# MCU_CPT2_AGGR0_STP2ATB_CFG register map
Vendor: Texas Instruments
Peripheral module from a debugger description file (folder am62P).
Registers are 32-bit, access per field, reset 0x4 unless marked. A register's access mark holds for its fields unless they carry their own. Offsets are as the file gives them; lines under a group give offsets from that group; [hi:lo] are bit positions; {n}, {i} and the like mark numbered series; 'fields as' and 'values as' point back to an identical list; <NAME> marks a mode.

## MCU_CPT2_AGGR0_STP2ATB_CFG
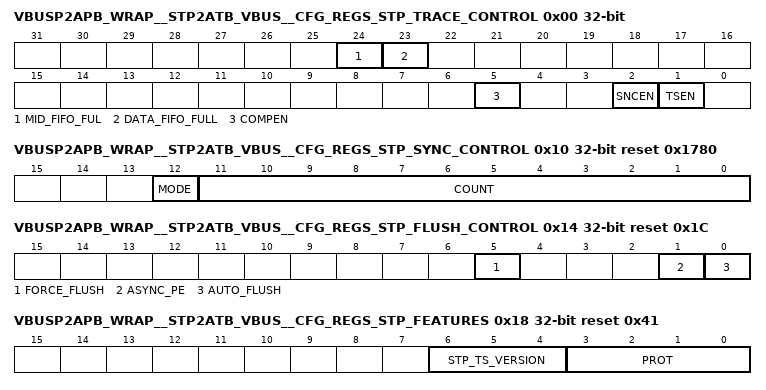
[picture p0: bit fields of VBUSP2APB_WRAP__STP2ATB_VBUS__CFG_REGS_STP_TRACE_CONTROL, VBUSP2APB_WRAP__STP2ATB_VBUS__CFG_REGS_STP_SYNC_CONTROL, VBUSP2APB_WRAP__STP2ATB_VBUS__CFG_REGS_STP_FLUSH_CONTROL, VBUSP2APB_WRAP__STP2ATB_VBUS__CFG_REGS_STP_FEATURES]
0x00 VBUSP2APB_WRAP__STP2ATB_VBUS__CFG_REGS_STP_TRACE_CONTROL — This register contains the control and status settings for STP Trace control register. MID_Fifofull indicates status of internal Initiator/Channel Fifo as full. Data_Fifofull indicates the status of internal Data Fifo as full. It is possible that if MID_Fifofull is full and when new initiator_id is seen on STPMI i/f, the data will not be accepted as MID is full. It will wait for MID to be read out corresponding to Data.
  [24] MID_FIFO_FUL ro, [23] DATA_FIFO_FULL ro, [5] COMPEN rw, [2] SNCEN ro, [1] TSEN rw
0x04 VBUSP2APB_WRAP__STP2ATB_VBUS__CFG_REGS_STP_TRACE_ID reset 0x0 — This register contains the trace id register settings. This value is sampled from input and is exported on ATB interface as ATID field. This is usually programmed only when top-level configuration errors results in collision between ID's.
  [6:0] TRACEID rw
0x10 VBUSP2APB_WRAP__STP2ATB_VBUS__CFG_REGS_STP_SYNC_CONTROL reset 0x1780 — This register contains the periodic interval after which an ASYNC packet is exported over ATB interface. This counter register controls the interval between synchronization packets. The number of bytes between which a sync packet is sent based on this counter value. Writing a value of 0x0 disables the synchronization counter, however if the client has any other synchronization scheme, that will continue to operate. When this register is written, STPMI2ATB will immediately perform synchronization and reset the counter value to the newly programmed value ensuring subsequent synchronization occurs in the period programmed. This async requests will result in a Initiator switch. A async request will result in async packet followed by VERSION packet which is followed by a new M8/C8 packet before any Dx packet is sent.
  [12] MODE rw, [11:0] COUNT rw
0x14 VBUSP2APB_WRAP__STP2ATB_VBUS__CFG_REGS_STP_FLUSH_CONTROL reset 0x1C — This register contains the bits to indicate flush in STPMI2ATB. It also controls priority control for other conditions in STPMI2ATB.
  [5] FORCE_FLUSH rw, [1] ASYNC_PE rw, [0] AUTO_FLUSH rw
0x18 VBUSP2APB_WRAP__STP2ATB_VBUS__CFG_REGS_STP_FEATURES ro reset 0x41 — This register contains the bits to indicate the features implemented in STPMI2ATB. It shows the VERSION packet implemented based on STP2.0 type of encoding timestamp packet. It also indicates what protocol is followed in the IP.
  [6:4] STP_TS_VERSION, [3:0] PROT
